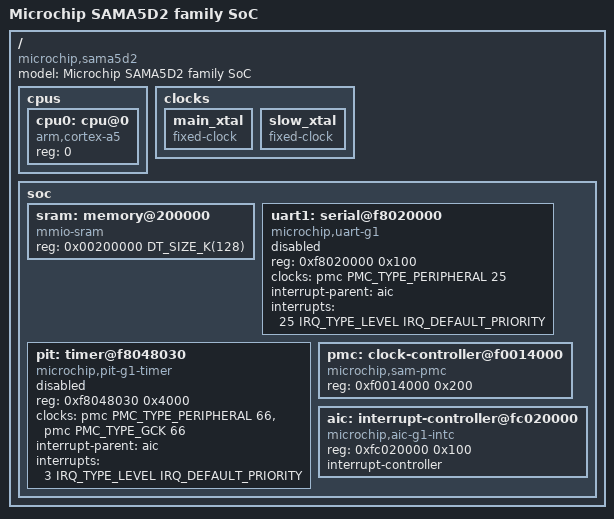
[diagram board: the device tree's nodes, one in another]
/*
 * Copyright (C) 2025-2026 Microchip Technology Inc. and its subsidiaries
 *
 * SPDX-License-Identifier: Apache-2.0
 *
 */

#include <arm/armv7-a.dtsi>
#include <mem.h>
#include <zephyr/dt-bindings/clock/microchip_sam_pmc.h>
#include <zephyr/dt-bindings/interrupt-controller/arm-gic.h>

/ {
	model = "Microchip SAMA5D2 family SoC";
	compatible = "microchip,sama5d2";

	cpus {
		#address-cells = <1>;
		#size-cells = <0>;

		cpu0: cpu@0 {
			device_type = "cpu";
			compatible = "arm,cortex-a5";
			reg = <0>;
		};
	};

	clocks {
		main_xtal: main_xtal {
			compatible = "fixed-clock";
			#clock-cells = <0>;
		};

		slow_xtal: slow_xtal {
			compatible = "fixed-clock";
			#clock-cells = <0>;
		};
	};

	soc {
		sram: memory@200000 {
			compatible = "mmio-sram";
			reg = <0x00200000 DT_SIZE_K(128)>;
		};

		uart1: serial@f8020000 {
			compatible = "microchip,uart-g1";
			reg = <0xf8020000 0x100>;
			clocks = <&pmc PMC_TYPE_PERIPHERAL 25>;
			interrupt-parent = <&aic>;
			interrupts = <25 IRQ_TYPE_LEVEL IRQ_DEFAULT_PRIORITY>;
			status = "disabled";
		};

		pit: timer@f8048030 {
			compatible = "microchip,pit-g1-timer";
			reg = <0xf8048030 0x4000>;
			clocks = <&pmc PMC_TYPE_PERIPHERAL 66>, <&pmc PMC_TYPE_GCK 66>;
			clock-names = "pclk", "gclk";
			interrupt-parent = <&aic>;
			interrupts = <3 IRQ_TYPE_LEVEL IRQ_DEFAULT_PRIORITY>;
			status = "disabled";
		};

		pmc: clock-controller@f0014000 {
			compatible = "microchip,sam-pmc";
			reg = <0xf0014000 0x200>;
			#clock-cells = <2>;
		};

		aic: interrupt-controller@fc020000 {
			compatible = "microchip,aic-g1-intc";
			reg = <0xfc020000 0x100>;
			interrupt-controller;
			#interrupt-cells = <3>;
		};
	};
};
